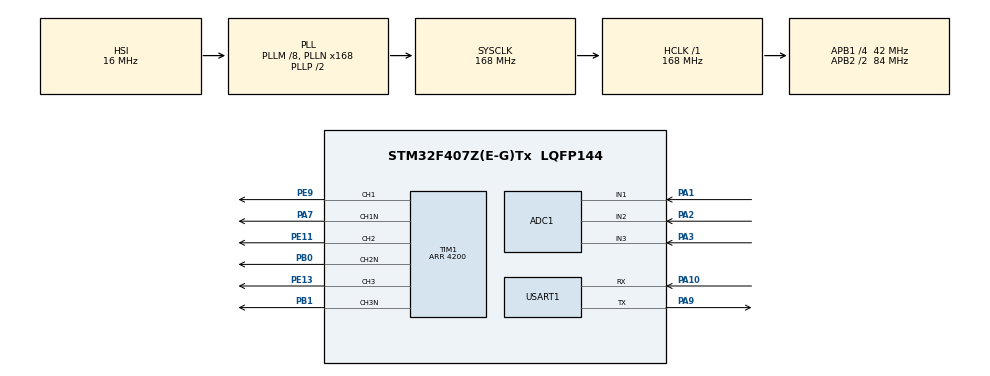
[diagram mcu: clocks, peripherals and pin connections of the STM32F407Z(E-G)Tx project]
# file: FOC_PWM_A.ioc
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ADC1.Channel-3\#ChannelRegularConversion=ADC_CHANNEL_1
ADC1.Channel-4\#ChannelRegularConversion=ADC_CHANNEL_2
ADC1.Channel-5\#ChannelRegularConversion=ADC_CHANNEL_3
ADC1.ClockPrescaler=ADC_CLOCK_SYNC_PCLK_DIV6
ADC1.ContinuousConvMode=ENABLE
ADC1.DMAContinuousRequests=ENABLE
ADC1.EOCSelection=ADC_EOC_SEQ_CONV
ADC1.NbrOfConversion=3
ADC1.NbrOfConversionFlag=1
ADC1.Rank-3\#ChannelRegularConversion=1
ADC1.Rank-4\#ChannelRegularConversion=2
ADC1.Rank-5\#ChannelRegularConversion=3
ADC1.SamplingTime-3\#ChannelRegularConversion=ADC_SAMPLETIME_144CYCLES
ADC1.SamplingTime-4\#ChannelRegularConversion=ADC_SAMPLETIME_144CYCLES
ADC1.SamplingTime-5\#ChannelRegularConversion=ADC_SAMPLETIME_144CYCLES
ADC1.ScanConvMode=ENABLE
ADC1.master=1
Dma.ADC1.0.Direction=DMA_PERIPH_TO_MEMORY
Dma.ADC1.0.FIFOMode=DMA_FIFOMODE_DISABLE
Dma.ADC1.0.Instance=DMA2_Stream0
Dma.ADC1.0.MemDataAlignment=DMA_MDATAALIGN_WORD
Dma.ADC1.0.MemInc=DMA_MINC_ENABLE
Dma.ADC1.0.Mode=DMA_CIRCULAR
Dma.ADC1.0.PeriphDataAlignment=DMA_PDATAALIGN_WORD
Dma.ADC1.0.PeriphInc=DMA_PINC_DISABLE
Dma.ADC1.0.Priority=DMA_PRIORITY_LOW
Dma.Request0=ADC1
Mcu.Family=STM32F4
Mcu.Name=STM32F407Z(E-G)Tx
Mcu.Package=LQFP144
NVIC.ADC_IRQn=true\:0\:0\:false\:false\:true\:true\:true\:true
NVIC.DMA2_Stream0_IRQn=true\:0\:0\:false\:false\:true\:false\:true\:true
NVIC.PriorityGroup=NVIC_PRIORITYGROUP_4
NVIC.TIM8_UP_TIM13_IRQn=true\:15\:0\:false\:false\:true\:false\:true\:true
NVIC.TimeBase=TIM8_UP_TIM13_IRQn
NVIC.TimeBaseIP=TIM8
PA1.Signal=ADCx_IN1
PA10.Mode=Asynchronous
PA10.Signal=USART1_RX
PA13.Mode=Serial_Wire
PA13.Signal=SYS_JTMS-SWDIO
PA14.Mode=Serial_Wire
PA14.Signal=SYS_JTCK-SWCLK
PA2.Signal=ADCx_IN2
PA3.Signal=ADCx_IN3
PA7.Mode=PWM Generation1 CH1 CH1N
PA7.Signal=TIM1_CH1N
PA9.Mode=Asynchronous
PA9.Signal=USART1_TX
PB0.Mode=PWM Generation2 CH2 CH2N
PB0.Signal=TIM1_CH2N
PB1.Mode=PWM Generation3 CH3 CH3N
PB1.Signal=TIM1_CH3N
PC14-OSC32_IN.Mode=LSE-External-Oscillator
PC14-OSC32_IN.Signal=RCC_OSC32_IN
PC15-OSC32_OUT.Mode=LSE-External-Oscillator
PC15-OSC32_OUT.Signal=RCC_OSC32_OUT
PE11.Signal=S_TIM1_CH2
PE13.Signal=S_TIM1_CH3
PE9.Signal=S_TIM1_CH1
PH0-OSC_IN.Mode=HSE-External-Oscillator
PH0-OSC_IN.Signal=RCC_OSC_IN
PH1-OSC_OUT.Mode=HSE-External-Oscillator
PH1-OSC_OUT.Signal=RCC_OSC_OUT
ProjectManager.HeapSize=0x200
ProjectManager.StackSize=0x400
ProjectManager.TargetToolchain=MDK-ARM V5.32
RCC.48MHZClocksFreq_Value=84000000
RCC.AHBFreq_Value=168000000
RCC.APB1CLKDivider=RCC_HCLK_DIV4
RCC.APB1Freq_Value=42000000
RCC.APB1TimFreq_Value=84000000
RCC.APB2CLKDivider=RCC_HCLK_DIV2
RCC.APB2Freq_Value=84000000
RCC.APB2TimFreq_Value=168000000
RCC.CortexFreq_Value=168000000
RCC.HCLKFreq_Value=168000000
RCC.HSE_VALUE=25000000
RCC.HSI_VALUE=16000000
RCC.PLLM=8
RCC.PLLN=168
RCC.SYSCLKFreq_VALUE=168000000
RCC.SYSCLKSource=RCC_SYSCLKSOURCE_PLLCLK
RCC.VCOOutputFreq_Value=336000000
SH.ADCx_IN1.0=ADC1_IN1,IN1
SH.ADCx_IN2.0=ADC1_IN2,IN2
SH.ADCx_IN3.0=ADC1_IN3,IN3
SH.S_TIM1_CH1.0=TIM1_CH1,PWM Generation1 CH1 CH1N
SH.S_TIM1_CH2.0=TIM1_CH2,PWM Generation2 CH2 CH2N
SH.S_TIM1_CH3.0=TIM1_CH3,PWM Generation3 CH3 CH3N
TIM1.Channel-PWM\ Generation1\ CH1\ CH1N=TIM_CHANNEL_1
TIM1.Channel-PWM\ Generation2\ CH2\ CH2N=TIM_CHANNEL_2
TIM1.Channel-PWM\ Generation3\ CH3\ CH3N=TIM_CHANNEL_3
TIM1.Channel-PWM\ Generation4\ No\ Output=TIM_CHANNEL_4
TIM1.CounterMode=TIM_COUNTERMODE_CENTERALIGNED2
TIM1.DeadTime=15
TIM1.Period=4200
TIM1.RepetitionCounter=1
USART1.VirtualMode=VM_ASYNC
VP_SYS_VS_tim8.Mode=TIM8
VP_TIM1_VS_ClockSourceINT.Mode=Internal
VP_TIM1_VS_no_output4.Mode=PWM Generation4 No Output
board=custom

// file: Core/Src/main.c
/* USER CODE BEGIN Header */
/**
  ******************************************************************************
  * @file           : main.c
  * @brief          : Main program body
  ******************************************************************************
  * @attention
  *
  * Copyright (c) 2023 STMicroelectronics.
  * All rights reserved.
  *
  * This software is licensed under terms that can be found in the LICENSE file
  * in the root directory of this software component.
  * If no LICENSE file comes with this software, it is provided AS-IS.
  *
  ******************************************************************************
  */
/* USER CODE END Header */
#include "main.h"
#include "adc.h"
#include "dma.h"
#include "tim.h"
#include "usart.h"
#include "gpio.h"

/* USER CODE BEGIN Includes */
#include "ZH_FOC.h"
#include "Drive.h"
/* USER CODE END Includes */

void SystemClock_Config(void);

int main(void)
{

  /* MCU Configuration--------------------------------------------------------*/

  /* Reset of all peripherals, Initializes the Flash interface and the Systick. */
  HAL_Init();

  /* Configure the system clock */
  SystemClock_Config();

  /* Initialize all configured peripherals */
  MX_GPIO_Init();
  MX_DMA_Init();
  MX_TIM1_Init();
  MX_ADC1_Init();
  MX_USART1_UART_Init();
  /* USER CODE BEGIN 2 */
		MOTOR1_PWM_Init();
		FOC_Iint();		//初始化外设
  /* USER CODE END 2 */

  /* Infinite loop */
  while (1)
  {

    /* USER CODE BEGIN 3 */
//			int i=0;
//		for(i=0;i<4200;i++)
//		{
//			HAL_Delay(1);
//		__HAL_TIM_SET_COMPARE(&htim1, TIM_CHANNEL_1,i);
//		__HAL_TIM_SET_COMPARE(&htim1, TIM_CHANNEL_2,i);
//		__HAL_TIM_SET_COMPARE(&htim1, TIM_CHANNEL_3,i);
//		}
//		for(i=4200;i>0;i--)
//		{
//				HAL_Delay(1);
//		__HAL_TIM_SET_COMPARE(&htim1, TIM_CHANNEL_1,i);
//		__HAL_TIM_SET_COMPARE(&htim1, TIM_CHANNEL_2,i);
//		__HAL_TIM_SET_COMPARE(&htim1, TIM_CHANNEL_3,i);
//		}
//
	velocityOpenloop(5000);
		printf("d: %d, %d, %d\n",ADCValueDMA[0],ADCValueDMA[1],ADCValueDMA[2]);
//	printf("%d\n",(unsigned long)HAL_GetTick());
//	printf("%d\n",(unsigned long)HAL_GetTick());
//	HAL_Delay(1000);
  }
  /* USER CODE END 3 */
}

void SystemClock_Config(void)
{
  RCC_OscInitTypeDef RCC_OscInitStruct = {0};
  RCC_ClkInitTypeDef RCC_ClkInitStruct = {0};

  /** Configure the main internal regulator output voltage
  */
  __HAL_RCC_PWR_CLK_ENABLE();
  __HAL_PWR_VOLTAGESCALING_CONFIG(PWR_REGULATOR_VOLTAGE_SCALE1);

  /** Initializes the RCC Oscillators according to the specified parameters
  * in the RCC_OscInitTypeDef structure.
  */
  RCC_OscInitStruct.OscillatorType = RCC_OSCILLATORTYPE_HSI;
  RCC_OscInitStruct.HSIState = RCC_HSI_ON;
  RCC_OscInitStruct.HSICalibrationValue = RCC_HSICALIBRATION_DEFAULT;
  RCC_OscInitStruct.PLL.PLLState = RCC_PLL_ON;
  RCC_OscInitStruct.PLL.PLLSource = RCC_PLLSOURCE_HSI;
  RCC_OscInitStruct.PLL.PLLM = 8;
  RCC_OscInitStruct.PLL.PLLN = 168;
  RCC_OscInitStruct.PLL.PLLP = RCC_PLLP_DIV2;
  RCC_OscInitStruct.PLL.PLLQ = 4;
  if (HAL_RCC_OscConfig(&RCC_OscInitStruct) != HAL_OK)
  {
    Error_Handler();
  }

  /** Initializes the CPU, AHB and APB buses clocks
  */
  RCC_ClkInitStruct.ClockType = RCC_CLOCKTYPE_HCLK|RCC_CLOCKTYPE_SYSCLK
                              |RCC_CLOCKTYPE_PCLK1|RCC_CLOCKTYPE_PCLK2;
  RCC_ClkInitStruct.SYSCLKSource = RCC_SYSCLKSOURCE_PLLCLK;
  RCC_ClkInitStruct.AHBCLKDivider = RCC_SYSCLK_DIV1;
  RCC_ClkInitStruct.APB1CLKDivider = RCC_HCLK_DIV4;
  RCC_ClkInitStruct.APB2CLKDivider = RCC_HCLK_DIV2;

  if (HAL_RCC_ClockConfig(&RCC_ClkInitStruct, FLASH_LATENCY_5) != HAL_OK)
  {
    Error_Handler();
  }
}

void HAL_TIM_PeriodElapsedCallback(TIM_HandleTypeDef *htim)
{
  if (htim->Instance == TIM8) {
    HAL_IncTick();
  }
}

void Error_Handler(void)
{
  __disable_irq();
  while (1)
  {
  }
}
